AUTOSAR XML (schema 00048)
package /SecurityArchitecture/ComponentTypes
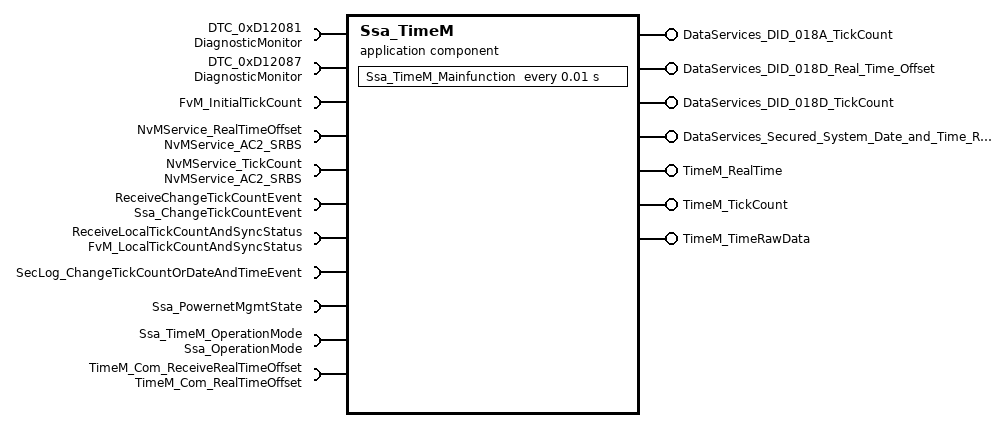
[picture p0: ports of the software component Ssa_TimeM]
  application sw component type Ssa_TimeM
    7 x provide port:
      DataServices_DID_018A_TickCount: provided-com-specs=[{operation=ConditionCheckRead, queue-length=1}, {operation=ReadData, queue-length=1}], provided-interface=DataServices_DID_018A_TickCount  # Reads local tick-count and passes it to given data parameter. Connect to corresponding Dcm port.
      DataServices_DID_018D_Real_Time_Offset: provided-com-specs=[{operation=ConditionCheckRead, queue-length=1}, {operation=ReadData, queue-length=1}], provided-interface=DataServices_DID_018D_Real_Time_Offset  # Reads the date and time reference of the real-time offset and passes it to given data parameter. Connect to corresponding Dcm port.
      DataServices_DID_018D_TickCount: provided-com-specs=[{operation=ConditionCheckRead, queue-length=1}, {operation=ReadData, queue-length=1}], provided-interface=DataServices_DID_018D_TickCount  # Reads the tick-count offset of the real-time offset and passes it to given data parameter. Connect to corresponding Dcm port.
      DataServices_Secured_System_Date_and_Time_Read_GeneralizedTime: provided-com-specs=[{operation=ConditionCheckRead, queue-length=1}, {operation=ReadData, queue-length=1}], provided-interface=DataServices_Secured_System_Date_and_Time_Read_GeneralizedTime  # Reads the secured date and time and passes it in GeneralizedTime format to given data parameter. Connect to corresponding Dcm port.
      TimeM_RealTime: provided-com-specs=[{operation=Compare, queue-length=1}, {operation=Get, queue-length=1}, {operation=Set, queue-length=1}], provided-interface=TimeM_RealTime
      TimeM_TickCount: server-com-spec{operation=Get, queue-length=1}, provided-interface=TimeM_TickCount
      TimeM_TimeRawData: provided-interface=TimeM_TimeRawData
        provided-com-specs:
          operation=Get, queue-length=1
          operation=Set, queue-length=1
          operation=ResetLocalTickCount, queue-length=1
    11 x require port:
      DTC_0xD12081: required-com-specs=[ResetEventDebounceStatus, ResetEventStatus, SetEventStatus], required-interface=DiagnosticMonitor  # Set an Event Status to failed if for the configured timespan tick-count messages were received and authenticated but not accepted due to turning back beyond the allowed amount. Connect to corresponding event of Dem.
      DTC_0xD12087: required-com-specs=[ResetEventDebounceStatus, ResetEventStatus, SetEventStatus], required-interface=DiagnosticMonitor  # Set an Event Status to failed if for the configured timespan tick-count messages were received but could not be authenticated or were not received at all. Connect to corresponding event of Dem.
      FvM_InitialTickCount: client-com-spec=Set, required-interface=FvM_InitialTickCount
      NvMService_RealTimeOffset: required-com-specs=[GetErrorStatus, ReadBlock, SetRamBlockStatus, WriteBlock], required-interface=NvMService_AC2_SRBS  # Controlling the NvM Block which stores the real time offset. Connect to NvM block storing the real time offset.
      NvMService_TickCount: required-com-specs=[GetErrorStatus, ReadBlock, SetRamBlockStatus, WriteBlock], required-interface=NvMService_AC2_SRBS  # Controlling the NvM Block which stores the tick count. Connect to NvM block storing the tick count.
      ReceiveChangeTickCountEvent: required-interface=Ssa_ChangeTickCountEvent  # Configuration Variant(s): Not in VSM.
        required-com-specs:
          data-element=Id, filter=data-filter-type=ALWAYS, init-value=SSA_CHANGETICKCOUNTEVENTID_UNDEFINED
          data-element=TickCount, filter=data-filter-type=ALWAYS, init-value=constant-reference=Ssa_Init_Zero_5Byte
      ReceiveLocalTickCountAndSyncStatus: nonqueued-receiver-com-spec{data-element=Data, filter=data-filter-type=ALWAYS, init-value=constant-reference=Ssa_Init_LocalTickCountAndSyncStatus}, required-interface=FvM_LocalTickCountAndSyncStatus
      SecLog_ChangeTickCountOrDateAndTimeEvent: client-com-spec=ChangeTickCountOrDateAndTime, required-interface=SecLog_ChangeTickCountOrDateAndTimeEvent
      Ssa_PowernetMgmtState: nonqueued-receiver-com-spec{data-element=PN14_DDP_Sw_Stat_ST3, filter=data-filter-type=ALWAYS, init-value=constant-reference=Ssa_Init_PowernetMgmtState}, required-interface=Ssa_PowernetMgmtState
      Ssa_TimeM_OperationMode: mode-switch-receiver-com-spec=Mode, required-interface=Ssa_OperationMode  # The operation of the TimeM main function is controlled by the modes set at this service port. E.g. connect to BswM and create appropriate rule.
      TimeM_Com_ReceiveRealTimeOffset: nonqueued-receiver-com-spec{data-element=realTimeOffset, filter=data-filter-type=ALWAYS, init-value=constant-reference=Ssa_Init_Zero_12Byte}, required-interface=TimeM_Com_RealTimeOffset  # Configuration Variant(s): Not in VSM.
    behavior Ssa_TimeM_InternalBehavior: data-type-mapping=SSATypeMappingSet
      exclusive area TimeM_ExclusiveArea
      ar-typed-per-instance-memorys:
        5 x data:
          RealTimeOffset: type=TimeM_RealTimeOffsetType
          RealTimeOffsetMirror: type=TimeM_RealTimeOffsetType
          TickCount: type=uint64  # Stores the current TickCount.
          TickCountMirror: type=uint64  # Used as mirror before writing with NvM.
          TickCountValueToBeStoredToNvM: type=uint64  # This value is used to store the tickcount at the time the NvM WriteRequest is set.
      data received event DRT_Ssa_TimeM_Com_ReceiveRealTimeOffset_TimeM_Com_ReceiveRealTimeOffset_realTimeOffset: start-on-event=Ssa_TimeM_Com_ReceiveRealTimeOffset, data=TimeM_Com_ReceiveRealTimeOffset.realTimeOffset
      8 x operation invoked event:
        OIT_DataServices_DID_018A_TickCount_ConditionCheckRead_DataServices_DID_018A_TickCount_ConditionCheckRead: start-on-event=Ssa_TimeM_DataServices_DID_018A_TickCount_ConditionCheckRead, operation=DataServices_DID_018A_TickCount.ConditionCheckRead
        OIT_DataServices_DID_018A_TickCount_ReadData_DataServices_DID_018A_TickCount_ReadData: start-on-event=Ssa_TimeM_DataServices_DID_018A_TickCount_ReadData, operation=DataServices_DID_018A_TickCount.ReadData
        OIT_DataServices_DID_018D_Real_Time_Offset_ConditionCheckRead_DataServices_DID_018D_Real_Time_Offset_ConditionCheckRead: start-on-event=Ssa_TimeM_DataServices_DID_018D_RealTimeOffset_DateTime_ConditionCheckRead, operation=DataServices_DID_018D_Real_Time_Offset.ConditionCheckRead
        OIT_DataServices_DID_018D_Real_Time_Offset_ReadData_DataServices_DID_018D_Real_Time_Offset_ReadData: start-on-event=Ssa_TimeM_DataServices_DID_018D_RealTimeOffset_DateTime_ReadData, operation=DataServices_DID_018D_Real_Time_Offset.ReadData
        OIT_DataServices_DID_018D_TickCount_ConditionCheckRead_DataServices_DID_018D_TickCount_ConditionCheckRead: start-on-event=Ssa_TimeM_DataServices_DID_018D_RealTimeOffset_TickCount_ConditionCheckRead, operation=DataServices_DID_018D_TickCount.ConditionCheckRead
        OIT_DataServices_DID_018D_TickCount_ReadData_DataServices_DID_018D_TickCount_ReadData: start-on-event=Ssa_TimeM_DataServices_DID_018D_RealTimeOffset_TickCount_ReadData, operation=DataServices_DID_018D_TickCount.ReadData
        OIT_TimeM_DataServices_Secured_System_Date_and_Time_Read_GeneralizedTime_ConditionCheckRead_DataServices_Secured_System_6BD121B0: start-on-event=Ssa_TimeM_DataServices_Secured_System_Date_and_Time_Read_GeneralizedTime_ConditionCheckRead, operation=DataServices_Secured_System_Date_and_Time_Read_GeneralizedTime.ConditionCheckRead
        OIT_TimeM_DataServices_Secured_System_Date_and_Time_Read_GeneralizedTime_ReadData_DataServices_Secured_System_Date_and_TA99C6FF7: start-on-event=Ssa_TimeM_DataServices_Secured_System_Date_and_Time_Read_GeneralizedTime_ReadData, operation=DataServices_Secured_System_Date_and_Time_Read_GeneralizedTime.ReadData
      init event TimeM_InitEvent: start-on-event=Ssa_TimeM_Init
      timing event TMT_TimeM_Mainfunction: start-on-event=Ssa_TimeM_Mainfunction, period=0.01
      data received event DRT_Runnable_Ssa_PowernetMgmtState_PowernetMgmtState: start-on-event=Ssa_TimeM_PowernetMgmtStateChanged, data=Ssa_PowernetMgmtState.PN14_DDP_Sw_Stat_ST3
      operation invoked event OIT_TimeM_RealTime_TimeM_CompareRealTime_TimeM_RealTime_TimeM_CompareRealTime: start-on-event=Ssa_TimeM_RealTime_Compare, operation=TimeM_RealTime.Compare
      operation invoked event OIT_TimeM_RealTime_TimeM_GetRealTime_TimeM_RealTime_TimeM_GetRealTime: start-on-event=Ssa_TimeM_RealTime_Get, operation=TimeM_RealTime.Get
      operation invoked event OIT_TimeM_RealTime_TimeM_SetRealTime_TimeM_RealTime_TimeM_SetRealTime: start-on-event=Ssa_TimeM_RealTime_Set, operation=TimeM_RealTime.Set
      data received event DRT_Ssa_TimeM_ReceiveChangeTickCountOrDateAndTimeEvent_ReceiveChangeTickCountEvent_Event: start-on-event=Ssa_TimeM_ReceiveChangeTickCountEvent, data=ReceiveChangeTickCountEvent.Id
      4 x operation invoked event:
        OIT_TimeM_Control_TimeM_GetLocalTimeBase_TimeM_Control_TimeM_GetLocalTimeBase: start-on-event=Ssa_TimeM_TickCount_Get, operation=TimeM_TickCount.Get
        OIT_TimeM_TimeRawData_Get_TimeM_TimeRawData_Get: start-on-event=Ssa_TimeM_TimeRawData_Get, operation=TimeM_TimeRawData.Get
        OIT_TimeM_TimeRawData_Set_TimeM_TimeRawData_Set: start-on-event=Ssa_TimeM_TimeRawData_Set, operation=TimeM_TimeRawData.Set
        OIT_TimeM_TimeRawData_ResetLocalTickCount_TimeM_TimeRawData_ResetLocalTickCount: start-on-event=Ssa_TimeM_TimeRawData_ResetLocalTickCount, operation=TimeM_TimeRawData.ResetLocalTickCount
      explicit-inter-runnable-variables:
        data TimeM_IrvTickCountSyncState: type=Ssa_TickCountSyncStateType, init-value=0
      port-api-options:
        enable-take-address=false, error-handling=NO-TRANSFORMER-ERROR-HANDLING, indirect-api=false, port=DataServices_DID_018A_TickCount
        enable-take-address=false, error-handling=NO-TRANSFORMER-ERROR-HANDLING, indirect-api=false, port=DataServices_Secured_System_Date_and_Time_Read_GeneralizedTime
        enable-take-address=false, error-handling=NO-TRANSFORMER-ERROR-HANDLING, indirect-api=false, port=DTC_0xD12081
        enable-take-address=false, error-handling=NO-TRANSFORMER-ERROR-HANDLING, indirect-api=false, port=NvMService_RealTimeOffset
        enable-take-address=false, error-handling=NO-TRANSFORMER-ERROR-HANDLING, indirect-api=false, port=NvMService_TickCount
        enable-take-address=false, error-handling=NO-TRANSFORMER-ERROR-HANDLING, indirect-api=false, port=SecLog_ChangeTickCountOrDateAndTimeEvent
        enable-take-address=false, error-handling=NO-TRANSFORMER-ERROR-HANDLING, indirect-api=false, port=TimeM_Com_ReceiveRealTimeOffset
        enable-take-address=false, error-handling=NO-TRANSFORMER-ERROR-HANDLING, indirect-api=false, port=TimeM_RealTime
        enable-take-address=false, error-handling=NO-TRANSFORMER-ERROR-HANDLING, indirect-api=false, port=TimeM_TickCount
        enable-take-address=false, error-handling=NO-TRANSFORMER-ERROR-HANDLING, indirect-api=false, port=TimeM_TimeRawData
      20 x runnable:
        Ssa_TimeM_Com_ReceiveRealTimeOffset: can-enter-exclusive-area=TimeM_ExclusiveArea  # Update the local offset value. Function is called when the Offset signal is received. The offset signal is sent with the VSM broadcast message. Configuration Variant(s): Not in VSM.
          data-receive-point-by-arguments:
            access REC_TimeM_Com_ReceiveRealTimeOffset_realTimeOffset: accessed-variable=TimeM_Com_ReceiveRealTimeOffset.realTimeOffset
          sync call SC_SecLog_ChangeTickCountOrDateAndTimeEvent_ChangeTickCountOrDateAndTime: operation=SecLog_ChangeTickCountOrDateAndTimeEvent.ChangeTickCountOrDateAndTime
        Ssa_TimeM_DataServices_DID_018A_TickCount_ConditionCheckRead
        Ssa_TimeM_DataServices_DID_018A_TickCount_ReadData: can-enter-exclusive-area=TimeM_ExclusiveArea
          read-local-variables:
            access READ_TimeM_IrvTickCountSyncState: accessed-variable=TimeM_IrvTickCountSyncState
        Ssa_TimeM_DataServices_DID_018D_RealTimeOffset_DateTime_ConditionCheckRead
        Ssa_TimeM_DataServices_DID_018D_RealTimeOffset_DateTime_ReadData: can-enter-exclusive-area=TimeM_ExclusiveArea
        Ssa_TimeM_DataServices_DID_018D_RealTimeOffset_TickCount_ConditionCheckRead
        Ssa_TimeM_DataServices_DID_018D_RealTimeOffset_TickCount_ReadData: can-enter-exclusive-area=TimeM_ExclusiveArea
        Ssa_TimeM_DataServices_Secured_System_Date_and_Time_Read_GeneralizedTime_ConditionCheckRead
        Ssa_TimeM_DataServices_Secured_System_Date_and_Time_Read_GeneralizedTime_ReadData: can-enter-exclusive-area=TimeM_ExclusiveArea
        Ssa_TimeM_Init  # Init function of TimeM
          4 x sync call:
            SC_Fvm_InitialTickCount_Set: operation=FvM_InitialTickCount.Set
            SC_NvMService_RealTimeOffset_GetErrorStatus: operation=NvMService_RealTimeOffset.GetErrorStatus
            SC_NvMService_TickCount_GetErrorStatus: operation=NvMService_TickCount.GetErrorStatus
            SC_SecLog_ChangeTickCountOrDateAndTimeEvent_ChangeTickCountOrDateAndTime: operation=SecLog_ChangeTickCountOrDateAndTimeEvent.ChangeTickCountOrDateAndTime
          written-local-variables:
            access WRITE_TimeM_IrvTickCountSyncState: accessed-variable=TimeM_IrvTickCountSyncState
        Ssa_TimeM_Mainfunction: can-enter-exclusive-area=TimeM_ExclusiveArea, mode-access-point=Ssa_TimeM_OperationMode.Mode  # Is called cyclically every 10 milliseconds. Updates the Local Time Base. VSM: When the Time Base signal should be sent: Get RTC time, update Local Time Base and call Com_SendSignal.
          data-receive-point-by-arguments:
            access REC_TimeM_ReceiveLocalTickCountAndSyncStatus_Data: accessed-variable=ReceiveLocalTickCountAndSyncStatus.Data
          5 x sync call:
            SC_NvMService_RealTimeOffset_GetErrorStatus: operation=NvMService_RealTimeOffset.GetErrorStatus
            SC_NvMService_RealTimeOffset_WriteBlock: operation=NvMService_RealTimeOffset.WriteBlock
            SC_NvMService_TickCount_GetErrorStatus: operation=NvMService_TickCount.GetErrorStatus
            SC_NvMService_TickCount_SetRamBlockStatus: operation=NvMService_TickCount.SetRamBlockStatus
            SC_NvMService_TickCount_WriteBlock: operation=NvMService_TickCount.WriteBlock
          written-local-variables:
            access WRITE_TimeM_IrvTickCountSyncState: accessed-variable=TimeM_IrvTickCountSyncState
        Ssa_TimeM_PowernetMgmtStateChanged: can-enter-exclusive-area=TimeM_ExclusiveArea
          data-receive-point-by-arguments:
            access REC_Ssa_PowernetMgmtState_PowernetMgmtState: accessed-variable=Ssa_PowernetMgmtState.PN14_DDP_Sw_Stat_ST3
        Ssa_TimeM_RealTime_Compare: can-be-invoked-concurrently=true
        Ssa_TimeM_RealTime_Get: can-enter-exclusive-area=TimeM_ExclusiveArea, can-be-invoked-concurrently=true
        Ssa_TimeM_RealTime_Set: can-enter-exclusive-area=TimeM_ExclusiveArea
          sync call SC_SecLog_ChangeTickCountOrDateAndTimeEvent_ChangeTickCountOrDateAndTime: operation=SecLog_ChangeTickCountOrDateAndTimeEvent.ChangeTickCountOrDateAndTime
        Ssa_TimeM_ReceiveChangeTickCountEvent  # Configuration Variant(s): Not in VSM.
          data-receive-point-by-arguments:
            access REC_ReceiveChangeTickCountEvent_Id: accessed-variable=ReceiveChangeTickCountEvent.Id
            access REC_ReceiveChangeTickCountOrDateAndTimeEvent_Data: accessed-variable=ReceiveChangeTickCountEvent.TickCount
          sync call SC_DTC_0xD12081_SetEventStatus: operation=DTC_0xD12081.SetEventStatus
          sync call SC_DTC_0xD12087_SetEventStatus: operation=DTC_0xD12087.SetEventStatus
          sync call SC_SecLog_ChangeTickCountOrDateAndTimeEvent_ChangeTickCountOrDateAndTime: operation=SecLog_ChangeTickCountOrDateAndTimeEvent.ChangeTickCountOrDateAndTime
        Ssa_TimeM_TickCount_Get: can-enter-exclusive-area=TimeM_ExclusiveArea, can-be-invoked-concurrently=true
        Ssa_TimeM_TimeRawData_Get: can-enter-exclusive-area=TimeM_ExclusiveArea, can-be-invoked-concurrently=true
        Ssa_TimeM_TimeRawData_Set: can-enter-exclusive-area=TimeM_ExclusiveArea, can-be-invoked-concurrently=true
          sync call SC_Fvm_InitialTickCount_Set: operation=FvM_InitialTickCount.Set
        Ssa_TimeM_TimeRawData_ResetLocalTickCount: can-enter-exclusive-area=TimeM_ExclusiveArea, can-be-invoked-concurrently=true
      swc service dependency NvM_TimeM_RealTimeOffset
        assigned-datas:
          role=ramBlock, used-data-element=RealTimeOffset
          role=defaultValue, used-parameter-element=NvM_TimeM_RealTimeOffset_DefaultValue
        service-needs:
          nv block needs NvM_TimeM_RealTimeOffset: ram-block-status-control=API, restore-at-start=true
      swc service dependency NvM_TimeM_TickCount
        assigned-datas:
          role=ramBlock, used-data-element=TickCount
          role=defaultValue, used-parameter-element=NvM_TimeM_LocalTimeBase_DefaultValue
        service-needs:
          nv block needs NvM_TimeM_TickCount: ram-block-status-control=API, restore-at-start=true, store-at-shutdown=true
      shared-parameters:
        parameter data prototype NvM_TimeM_LocalTimeBase_DefaultValue: type=uint64, init-value=0
        parameter data prototype NvM_TimeM_RealTimeOffset_DefaultValue: type=TimeM_RealTimeOffsetType, init-value=constant-reference=Ssa_TimeM_RealTimeOffestInit
  swc implementation Ssa_TimeM_Implementation: behavior=Ssa_TimeM_InternalBehavior
    code-descriptors:
      code Default: artifact-descriptors=autosar-engineering-object=category=SWSRC
